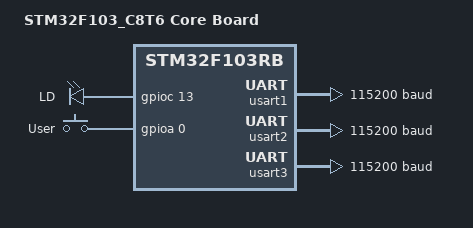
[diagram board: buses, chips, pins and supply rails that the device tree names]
/*
 * Copyright (c) 2017, embedjournal.com
 *
 * SPDX-License-Identifier: Apache-2.0
 */

/dts-v1/;
#include <st/stm32f103Xb.dtsi>

/ {
	model = "STM32F103_C8T6 Core Board";
	compatible = "st,stm32f103_core", "st,stm32_min_dev", "st,stm32f103rb";

	chosen {
		zephyr,console = &usart1;
		zephyr,sram = &sram0;
		zephyr,flash = &flash0;
	};

	leds {
		compatible = "gpio-leds";
		led: led@0 {
			gpios = <&gpioc 13 GPIO_INT_ACTIVE_HIGH>;
			label = "LD";
		};
	};

	gpio_keys {
		compatible = "gpio-keys";
		user_button: button@0 {
			gpios = <&gpioa 0 GPIO_INT_ACTIVE_HIGH>;
            label = "User";
		};
	};

	aliases {
		led0 = &led;
        sw0  = &user_button;
	};
};

&usart1 {
	current-speed = <115200>;
	pinctrl-0 = <&usart1_pins_a>;
	pinctrl-names = "default";
	status = "ok";
};

&usart2 {
	current-speed = <115200>;
	pinctrl-0 = <&usart2_pins_a>;
	pinctrl-names = "default";
};

&usart3 {
	current-speed = <115200>;
	pinctrl-0 = <&usart3_pins_a>;
	pinctrl-names = "default";
};



